# TLE984x register map
Vendor: Infineon Technologies AG; File version: 1.6
CPU: CM0 r0p0, little endian, no MPU, no FPU, 2 interrupt priority bits
Registers are 32-bit, read-write, no defined reset value unless marked. A register's access mark holds for its fields unless they carry their own. Offsets are from the block's base; [hi:lo] are bit positions; {n}, {i} and the like mark numbered series; 'fields as' and 'values as' point back to an identical list.

## PMU
Base 0x50004000
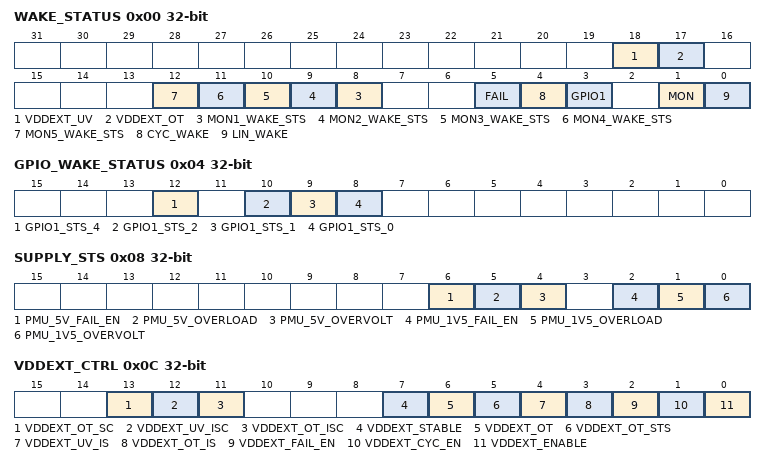
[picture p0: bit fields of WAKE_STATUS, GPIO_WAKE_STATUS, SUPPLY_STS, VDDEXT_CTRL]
0x00 WAKE_STATUS ro — Main wake status register
  [18] VDDEXT_UV — Wake VDDEXT Undervoltage
    0=No wake-up detected; 1=wake-up detected
  [17] VDDEXT_OT — Wake VDDEXT Overtemperature
    0=No wake-up detected; 1=wake-up detected
  [n+7] MON{n}_WAKE_STS (n=1..5) — Status of MON{n}
    0=No wake-up detected; 1=wake-up detected
  [5] FAIL — Wake-up after VDDEXT Fail
    0=No Wake-up occurred; 1=Wake-up occurred
  [4] CYC_WAKE — Wake-up caused by Cyclic Wake
    0=No Wake-up occurred; 1=Wake-up occurred
  [3] GPIO1 — Wake-up via GPIO1 which is a logical OR combination of all Wake_STS_GPIO1 bits
    0=No Wake-up occurred; 1=Wake-up occurred
  [1] MON — Wake-up via MON which is a logical OR combination of all Wake_STS_MON bits
    0=No Wake-up occurred; 1=Wake-up occurred
  [0] LIN_WAKE — Wake-up via LIN- Message
    0=No Wake-up occurred; 1=Wake-up occurred
0x04 GPIO_WAKE_STATUS ro — GPIO Port wake status register
  [all] fields
    0=No wake-up detected; 1=wake-up detected
  [12] GPIO1_STS_4 — Wake GPIO1_4
  [10] GPIO1_STS_2 — Wake GPIO1_2
  [9] GPIO1_STS_1 — Wake GPIO1_1
  [8] GPIO1_STS_0 — Wake GPIO1_0
0x08 SUPPLY_STS access per field — Voltage Reg Status Register
  [6] PMU_5V_FAIL_EN rw — Enabling of VDDP status information as interrupt source
    0=No interrupts are generated; 1=Interrupts are generated
  [5] PMU_5V_OVERLOAD ro — Overload at VDDP regulator
    0=No overload; 1=Overload
  [4] PMU_5V_OVERVOLT ro — Overvoltage at VDDP regulator
    0=No overvoltage; 1=Overvoltage
  [2] PMU_1V5_FAIL_EN rw — Enabling of VDDC status information as interrupt source
    0=No interrupts are generated; 1=Interrupts are generated
  [1] PMU_1V5_OVERLOAD ro — Overload at VDDC regulator
    0=No overload; 1=Overload
  [0] PMU_1V5_OVERVOLT ro — Overvoltage at VDDC regulator
    0=No overvoltage; 1=Overvoltage
0x0C VDDEXT_CTRL access per field — VDDEXT Control
  [13] VDDEXT_OT_SC wo — VDDEXT Supply Overtemperature Status clear
    1=VDDEXT Overtemperature status cleared; 0=VDDEXT Overtemperature status not cleared
  [12] VDDEXT_UV_ISC wo — VDDEXT Supply Undervoltage Interrupt Status clear
    1=VDDEXT Undervoltage cleared; 0=VDDEXT Undervoltage not cleared
  [11] VDDEXT_OT_ISC wo — VDDEXT Supply Overtemperature Interrupt Status clear
    1=VDDEXT Overtemperature cleared; 0=VDDEXT Overtemperature not cleared
  [7] VDDEXT_STABLE ro — VDDEXT Supply Stable
    0=VDDEXT not in stable condition; 1=VDDEXT in stable condition
  [6] VDDEXT_OT ro — VDDEXT Supply Overtemperature
    0=VDDEXT not in overtemperature condition; 1=VDDEXT in overtemperature condition
  [5] VDDEXT_OT_STS ro — VDDEXT Supply Overtemperature Status
    values as VDDEXT_OT
  [4] VDDEXT_UV_IS ro — VDDEXT Supply Undervoltage Interrupt Status
    0=VDDEXT not in undervoltage condition; 1=VDDEXT in undervoltage condition
  [3] VDDEXT_OT_IS ro — VDDEXT Supply Overtemperature Interrupt Status
    0=VDDEXT no overtemperature condition; 1=VDDEXT overtemperature condition
  [2] VDDEXT_FAIL_EN rw — Enabling of VDDEXT Supply status information as interrupt source
    0=VDDEXT fail interrupts are disabled; 1=VDDEXT fail Interrupts are enabled
  [1] VDDEXT_CYC_EN rw — VDDEXT Supply for Cyclic Sense Enable
    0=VDDEXT for cyclic sense disable; 1=VDDEXT for cyclic sense enable
  [0] VDDEXT_ENABLE rw — VDDEXT Supply Enable
    0=VDDEXT Supply disabled; 1=VDDEXT supply enabled
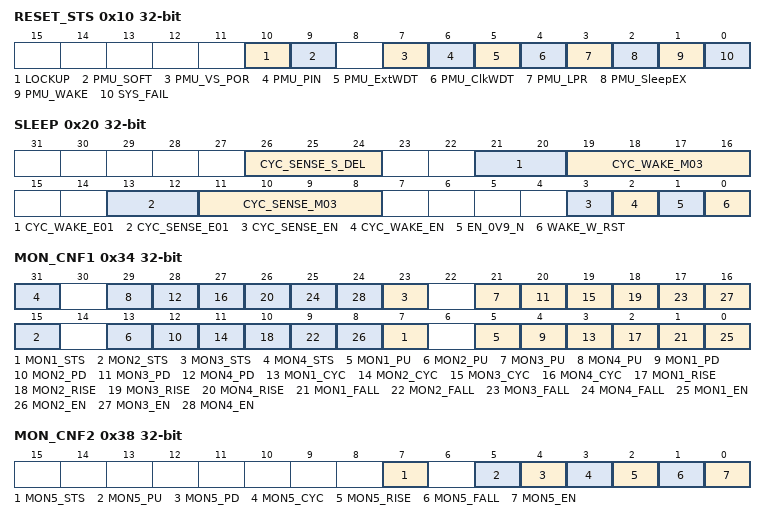
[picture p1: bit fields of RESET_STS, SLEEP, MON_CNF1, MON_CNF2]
0x10 RESET_STS — Reset Status Register
  [10] LOCKUP — Lockup-Reset Flag
    0=No Lockup-Reset executed; 1=Lockup-Reset executed
  [9] PMU_SOFT — Soft-Reset Flag
    0=No Soft-Reset executed; 1=Soft-Reset executed
  [7] PMU_VS_POR — Power-On Reset Flag
    0=No Power-On reset executed; 1=Power-On reset executed
  [6] PMU_PIN — PIN-Reset Flag
    0=No PIN-Reset executed; 1=PIN-Reset executed
  [5] PMU_ExtWDT — External Watchdog (WDT1) Reset Flag
    0=No External Watchdog reset executed; 1=External Watchdog reset executed
  [4] PMU_ClkWDT — Clock Watchdog (CLKWDT) Reset Flag
    0=No Clock Watchdog reset executed; 1=Clock Watchdog reset executed
  [3] PMU_LPR — Low Priority Resets
    0=Low Priority-Reset executed; 1=Low Priority executed
  [2] PMU_SleepEX — Flag which indicates a reset caused by Sleep-Exit
    0=No reset caused by Sleep-Exit executed; 1=Reset caused by Sleep-Exit executed
  [1] PMU_WAKE — Flag which indicates a reset caused by Stop-Exit
    0=No reset caused by Stop-Exit executed; 1=Reset caused by Stop-Exit executed
  [0] SYS_FAIL — Flag which indicates a reset caused by a System Fail reported in the corresponding Fail Register
    0=No reset caused by System Fail executed; 1=Reset caused by System Fail executed
0x20 SLEEP — PMU Sleep Behavior Register
  [26:24] CYC_SENSE_S_DEL — Sample Delay in Cyclic Sense Mode
    0=is 10 us; 1=is 20 us; 2=is 30 us; 3=is 40 us; 4=is 60 us; 5=is 80 us; 6=is 100 us; 7=is 150 us
  [21:20] CYC_WAKE_E01 — Exponent
    {v}=Exponent value is {v} (v=0..3)
  [19:16] CYC_WAKE_M03 — Mantissa
    0=Mantissa value is 1; 15=Mantissa value is 16
  [13:12] CYC_SENSE_E01 — Exponent
    {v}=Exponent value is {v} (v=0..3)
  [11:8] CYC_SENSE_M03 — Mantissa
    0=Mantissa value is 1; 15=Mantissa value is 16
  [3] CYC_SENSE_EN — Enabling Cyclic Sense
    0=Cyclic Sense disabled; 1=Cyclic Sense enabled
  [2] CYC_WAKE_EN — Enabling Cyclic Wake
    0=Cyclic Wake disabled; 1=Cyclic Wake enabled
  [1] EN_0V9_N — Enables the reduction of the VDDC regulator output to reduced voltage during Stop-Mode
    0=Output voltage reduction enabled; 1=Output voltage reduction disabled
  [0] WAKE_W_RST — Wake-up with reset execution
    0=Stop-Exit without reset execution; 1=Stop-Exit with reset execution
0x34 MON_CNF1 access per field — Settings Monitor 1-4
  [8n-1] MON{n}_STS ro (n=1..4) — MON{n} Status Input
    0=MON input has low status; 1=MON input has high status
  [8n-3] MON{n}_PU rw (n=1..4) — Pull-Up Current Source for MON{n} Input Enable
    0=Pull-up source disabled; 1=Pull-up source enabled
  [8n-4] MON{n}_PD rw (n=1..4) — Pull-Down Current Source for MON{n} Input Enable
    0=Pull-down source disabled; 1=Pull-down source enabled
  [8n-5] MON{n}_CYC rw (n=1..4) — MON{n} for Cycle Sense Enable
    0=Cycle Sense disabled; 1=Cycle Sense enabled
  [8n-6] MON{n}_RISE rw (n=1..4) — MON{n} Wake-up on Rising Edge Enable
    0=Wake-up disabled; 1=Wake-up enabled
  [8n-7] MON{n}_FALL rw (n=1..4) — MON{n} Wake-up on Falling Edge Enable
    0=Wake-up disabled; 1=Wake-up enabled
  [8n-8] MON{n}_EN rw (n=1..4) — MON{n} Enable
    0=MON{n} disabled; 1=MON{n} enabled
0x38 MON_CNF2 access per field — Settings Monitor 5
  [7] MON5_STS ro — MON5 Status Input
    0=MON input has low status; 1=MON input has high status
  [5] MON5_PU rw — Pull-Up Current Source for MON5 Input Enable
    0=Pull-up source disabled; 1=Pull-up source enabled
  [4] MON5_PD rw — Pull-Down Current Source for MON5 Input Enable
    0=Pull-down source disabled; 1=Pull-down source enabled
  [3] MON5_CYC rw — MON5 for Cycle Sense Enable
    0=Cycle Sense disabled; 1=Cycle Sense enabled
  [2] MON5_RISE rw — MON5 Wake-up on Rising Edge Enable
    0=Wake-up disabled; 1=Wake-up enabled
  [1] MON5_FALL rw — MON5 Wake-up on Falling Edge Enable
    0=Wake-up disabled; 1=Wake-up enabled
  [0] MON5_EN rw — MON5 Enable
    0=MON5 disabled; 1=MON5 enabled
0x50 LIN_WAKE_EN — LIN Wake Enable
  [7] LIN_EN — Lin Wake enable
    0=Disable; 1=Enable
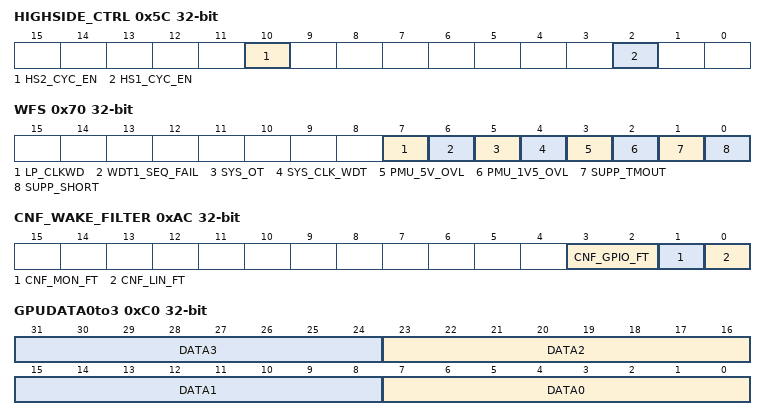
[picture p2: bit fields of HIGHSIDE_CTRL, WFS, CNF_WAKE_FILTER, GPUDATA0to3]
0x5C HIGHSIDE_CTRL — High-side Control Register
  [10] HS2_CYC_EN — High-side 2 switch enable for cyclic sense
    0=Disable; 1=Enable
  [2] HS1_CYC_EN — High-side 1 switch enable for cyclic sense
    0=Disable; 1=Enable
0x6C CNF_RST_TFB — Reset Blind Time Register
  [1:0] RST_TFB — Reset Pin Blind Time Selection Bits
    0=0.5 us typ; 1=1 us typ; 2=5 us typ; 3=31 us typ
0x70 WFS ro — WFS System Fail Register
  [7] LP_CLKWD
    0=ok; 1=fail
  [6] WDT1_SEQ_FAIL — External Watchdog (WDT1) Sequential Fail
    0=No Fail (System working properly); 1=Sequential Watchdog Fail (5 consecutive watchdog fails)
  [5] SYS_OT — System Overtemperature Indication Flag
    0=No Overtemperature (System ok); 1=Overtemperature (System Overtemperature)
  [4] SYS_CLK_WDT — System Clock (fsys)Watchdog Fail
    0=No System Clock Fail (fsys ok); 1=System Clock Fail (fsys failed)
  [3] PMU_5V_OVL — VDDP Overload Flag
    0=No Overload (VDDP ok); 1=Overload (VDDP Overload)
  [2] PMU_1V5_OVL — VDDC Overload Flag
    0=No Overload (VDDC ok); 1=Overload (Hall VDDC Overload)
  [1] SUPP_TMOUT — Supply Time Out
    0=Main Supply ok (VDDP or VDDC are in expected range); 1=Main Supply fail (VDDP or VDDC do not have stable operating point)
  [0] SUPP_SHORT — Supply Short
    0=Main Supply ok (VDDP or VDDC are in expected range); 1=Main Supply short (VDDP or VDDC do not have stable operating point)
0xAC CNF_WAKE_FILTER — PMU Wake-up Timing Register
  [3:2] CNF_GPIO_FT — Wake-up Filter time for General Purpose IO
    0=10 us filter time; 1=20 us filter time; 2=40 us filter time; 3=5 us filter time
  [1] CNF_MON_FT — Wake-up Filter time for Monitoring Inputs
    0=20 us filter time; 1=40 us filter time
  [0] CNF_LIN_FT — Wake-up Filter time for LIN WAKE
    0=30 us filter time; 1=50 us filter time
0xC0 GPUDATA0to3 — General Purpose User DATA0to3
  [8n+7:8n] DATA{n} (n=0..3) — DATA{n} Storage Byte
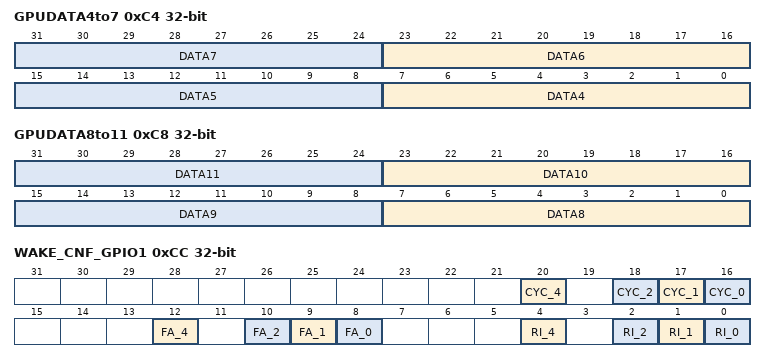
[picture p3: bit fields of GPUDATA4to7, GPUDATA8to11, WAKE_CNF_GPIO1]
0xC4 GPUDATA4to7 — General Purpose User DATA4to7
  [8n-25:8n-32] DATA{n} (n=4..7) — DATA{n} Storage Byte
0xC8 GPUDATA8to11 — General Purpose User DATA8to11
  [8n-57:8n-64] DATA{n} (n=8..11) — DATA{n} Storage Byte
0xCC WAKE_CNF_GPIO1 — Wake Configuration GPIO Port 1 Register
  [20] CYC_4 — GPIO1_4 input for cycle sense enable
    1=ENABLE (input for cycle sense enabled); 0=DISABLE (input for cycle sense disabled)
  [18] CYC_2 — GPIO1_2 input for cycle sense enable
    values as CYC_4
  [17] CYC_1 — GPIO1_1 input for cycle sense enable
    values as CYC_4
  [16] CYC_0 — GPIO1_0 input for cycle sense enable
    values as CYC_4
  [12] FA_4 — Port 1_4 Wake-up on Falling Edge enable
    1=ENABLE (wake-up enabled); 0=DISABLE (wake-up disabled)
  [10] FA_2 — Port 1_2 Wake-up on Falling Edge enable
    1=ENABLE (wake-up enabled); 0=DISABLE (wake-up disabled)
  [9] FA_1 — Port 1_1 Wake-up on Falling Edge enable
    1=ENABLE (wake-up enabled); 0=DISABLE (wake-up disabled)
  [8] FA_0 — Port 1_0 Wake-up on Falling Edge enable
    1=ENABLE (wake-up enabled); 0=DISABLE (wake-up disabled)
  [4] RI_4 — Port 1_4 Wake-up on Rising Edge enable
    1=ENABLE (wake-up enabled); 0=DISABLE (wake-up disabled)
  [2] RI_2 — Port 1_2 Wake-up on Rising Edge enable
    1=ENABLE (wake-up enabled); 0=DISABLE (wake-up disabled)
  [1] RI_1 — Port 1_1 Wake-up on Rising Edge enable
    1=ENABLE (wake-up enabled); 0=DISABLE (wake-up disabled)
  [0] RI_0 — Port 1_0 Wake-up on Rising Edge enable
    1=ENABLE (wake-up enabled); 0=DISABLE (wake-up disabled)
